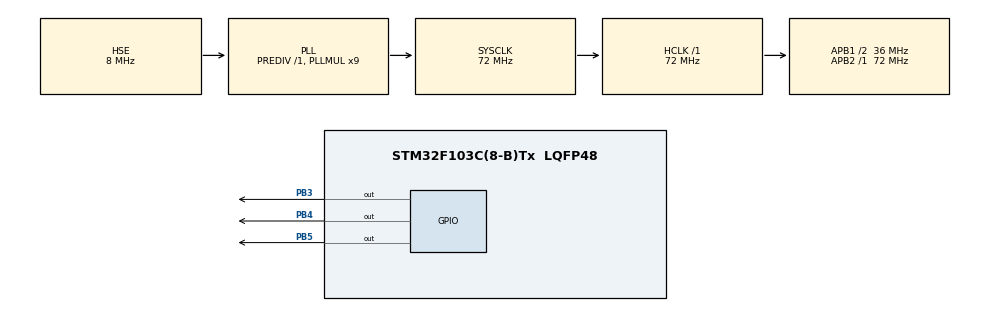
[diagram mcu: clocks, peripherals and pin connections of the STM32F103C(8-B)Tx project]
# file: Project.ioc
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FREERTOS.Tasks01=Task01,24,128,StartTask01,Default,NULL,Dynamic,NULL,NULL;Task02,16,128,StartTask02,Default,NULL,Dynamic,NULL,NULL
Mcu.Family=STM32F1
Mcu.Name=STM32F103C(8-B)Tx
Mcu.Package=LQFP48
NVIC.PriorityGroup=NVIC_PRIORITYGROUP_4
NVIC.TIM4_IRQn=true\:0\:0\:false\:false\:true\:false\:false\:true
NVIC.TimeBase=TIM4_IRQn
NVIC.TimeBaseIP=TIM4
PA13.Mode=Serial_Wire
PA13.Signal=SYS_JTMS-SWDIO
PA14.Mode=Serial_Wire
PA14.Signal=SYS_JTCK-SWCLK
PB3.Signal=GPIO_Output
PB4.Signal=GPIO_Output
PB5.Signal=GPIO_Output
PD0-OSC_IN.Mode=HSE-External-Oscillator
PD0-OSC_IN.Signal=RCC_OSC_IN
PD1-OSC_OUT.Mode=HSE-External-Oscillator
PD1-OSC_OUT.Signal=RCC_OSC_OUT
ProjectManager.HeapSize=0x200
ProjectManager.StackSize=0x400
ProjectManager.TargetToolchain=MDK-ARM V5.27
RCC.AHBFreq_Value=72000000
RCC.APB1CLKDivider=RCC_HCLK_DIV2
RCC.APB1Freq_Value=36000000
RCC.APB1TimFreq_Value=72000000
RCC.APB2Freq_Value=72000000
RCC.APB2TimFreq_Value=72000000
RCC.HCLKFreq_Value=72000000
RCC.PLLMUL=RCC_PLL_MUL9
RCC.PLLSourceVirtual=RCC_PLLSOURCE_HSE
RCC.SYSCLKFreq_VALUE=72000000
RCC.SYSCLKSource=RCC_SYSCLKSOURCE_PLLCLK
RCC.USBFreq_Value=72000000
VP_FREERTOS_VS_CMSIS_V2.Mode=CMSIS_V2
VP_SYS_VS_tim4.Mode=TIM4
board=custom

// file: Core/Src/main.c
/* USER CODE BEGIN Header */
/**
  ******************************************************************************
  * @file           : main.c
  * @brief          : Main program body
  ******************************************************************************
  * @attention
  *
  * <h2><center>&copy; Copyright (c) 2021 STMicroelectronics.
  * All rights reserved.</center></h2>
  *
  * This software component is licensed by ST under BSD 3-Clause license,
  * the "License"; You may not use this file except in compliance with the
  * License. You may obtain a copy of the License at:
  *                        opensource.org/licenses/BSD-3-Clause
  *
  ******************************************************************************
  */
/* USER CODE END Header */
#include "main.h"
#include "cmsis_os.h"
#include "gpio.h"

void SystemClock_Config(void);
void MX_FREERTOS_Init(void);

int main(void)
{

  /* MCU Configuration--------------------------------------------------------*/

  /* Reset of all peripherals, Initializes the Flash interface and the Systick. */
  HAL_Init();

  /* Configure the system clock */
  SystemClock_Config();

  /* Initialize all configured peripherals */
  MX_GPIO_Init();

  /* Init scheduler */
  osKernelInitialize();  /* Call init function for freertos objects (in freertos.c) */
  MX_FREERTOS_Init();
  /* Start scheduler */
  osKernelStart();

  /* We should never get here as control is now taken by the scheduler */
  /* Infinite loop */
  /* USER CODE BEGIN WHILE */
  while (1)
  {
		HAL_GPIO_WritePin(GPIOB, GPIO_PIN_3, GPIO_PIN_RESET);
		HAL_GPIO_WritePin(GPIOB, GPIO_PIN_4, GPIO_PIN_RESET);
		HAL_GPIO_WritePin(GPIOB, GPIO_PIN_5, GPIO_PIN_RESET);

		HAL_Delay(500);
		/*
		HAL_GPIO_WritePin(GPIOB, GPIO_PIN_3, GPIO_PIN_SET);
		HAL_GPIO_WritePin(GPIOB, GPIO_PIN_4, GPIO_PIN_SET);
		HAL_GPIO_WritePin(GPIOB, GPIO_PIN_5, GPIO_PIN_SET);

		HAL_Delay(500);*/

    /* USER CODE END WHILE */

  }
}

void SystemClock_Config(void)
{
  RCC_OscInitTypeDef RCC_OscInitStruct = {0};
  RCC_ClkInitTypeDef RCC_ClkInitStruct = {0};

  /** Initializes the RCC Oscillators according to the specified parameters
  * in the RCC_OscInitTypeDef structure.
  */
  RCC_OscInitStruct.OscillatorType = RCC_OSCILLATORTYPE_HSE;
  RCC_OscInitStruct.HSEState = RCC_HSE_ON;
  RCC_OscInitStruct.HSEPredivValue = RCC_HSE_PREDIV_DIV1;
  RCC_OscInitStruct.HSIState = RCC_HSI_ON;
  RCC_OscInitStruct.PLL.PLLState = RCC_PLL_ON;
  RCC_OscInitStruct.PLL.PLLSource = RCC_PLLSOURCE_HSE;
  RCC_OscInitStruct.PLL.PLLMUL = RCC_PLL_MUL9;
  if (HAL_RCC_OscConfig(&RCC_OscInitStruct) != HAL_OK)
  {
    Error_Handler();
  }
  /** Initializes the CPU, AHB and APB buses clocks
  */
  RCC_ClkInitStruct.ClockType = RCC_CLOCKTYPE_HCLK|RCC_CLOCKTYPE_SYSCLK
                              |RCC_CLOCKTYPE_PCLK1|RCC_CLOCKTYPE_PCLK2;
  RCC_ClkInitStruct.SYSCLKSource = RCC_SYSCLKSOURCE_PLLCLK;
  RCC_ClkInitStruct.AHBCLKDivider = RCC_SYSCLK_DIV1;
  RCC_ClkInitStruct.APB1CLKDivider = RCC_HCLK_DIV2;
  RCC_ClkInitStruct.APB2CLKDivider = RCC_HCLK_DIV1;

  if (HAL_RCC_ClockConfig(&RCC_ClkInitStruct, FLASH_LATENCY_2) != HAL_OK)
  {
    Error_Handler();
  }
}

void HAL_TIM_PeriodElapsedCallback(TIM_HandleTypeDef *htim)
{
  if (htim->Instance == TIM4) {
    HAL_IncTick();
  }
}

void Error_Handler(void)
{
}

/************************ (C) COPYRIGHT STMicroelectronics *****END OF FILE****/

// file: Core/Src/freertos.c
/* USER CODE BEGIN Header */
/**
  ******************************************************************************
  * File Name          : freertos.c
  * Description        : Code for freertos applications
  ******************************************************************************
  * @attention
  *
  * <h2><center>&copy; Copyright (c) 2021 STMicroelectronics.
  * All rights reserved.</center></h2>
  *
  * This software component is licensed by ST under Ultimate Liberty license
  * SLA0044, the "License"; You may not use this file except in compliance with
  * the License. You may obtain a copy of the License at:
  *                             www.st.com/SLA0044
  *
  ******************************************************************************
  */
/* USER CODE END Header */

#include "FreeRTOS.h"
#include "task.h"
#include "main.h"
#include "cmsis_os.h"

/* Definitions for Task01 */
osThreadId_t Task01Handle;
const osThreadAttr_t Task01_attributes = {
  .name = "Task01",
  .priority = (osPriority_t) osPriorityNormal,
  .stack_size = 128 * 4
};
/* Definitions for Task02 */
osThreadId_t Task02Handle;
const osThreadAttr_t Task02_attributes = {
  .name = "Task02",
  .priority = (osPriority_t) osPriorityBelowNormal,
  .stack_size = 128 * 4
};

void StartTask01(void *argument);
void StartTask02(void *argument);

void MX_FREERTOS_Init(void); /* (MISRA C 2004 rule 8.1) */

void MX_FREERTOS_Init(void) {

  /* Create the thread(s) */
  /* creation of Task01 */
  Task01Handle = osThreadNew(StartTask01, NULL, &Task01_attributes);

  /* creation of Task02 */
  Task02Handle = osThreadNew(StartTask02, NULL, &Task02_attributes);

}

void StartTask01(void *argument)
{
  for(;;)
  {
    osDelay(1);
  }
}

void StartTask02(void *argument)
{
  for(;;)
  {
    osDelay(1);
  }
}

/************************ (C) COPYRIGHT STMicroelectronics *****END OF FILE****/
